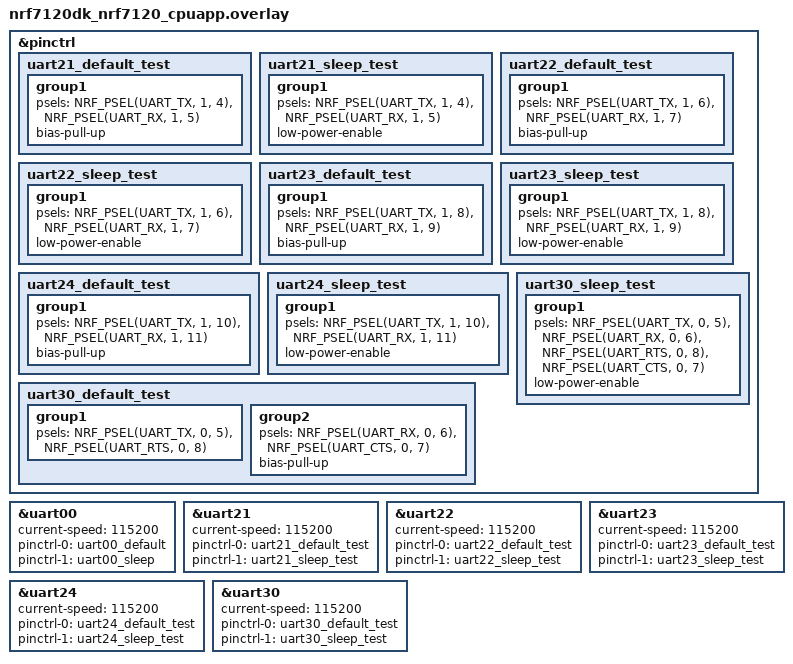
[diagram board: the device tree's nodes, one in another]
/*
 * Copyright (c) 2026 Nordic Semiconductor ASA
 *
 * SPDX-License-Identifier: LicenseRef-Nordic-5-Clause
 */

&pinctrl {
	uart21_default_test: uart21_default_test {
		group1 {
			psels = <NRF_PSEL(UART_TX, 1, 4)>,
				<NRF_PSEL(UART_RX, 1, 5)>;
			bias-pull-up;
		};
	};

	uart21_sleep_test: uart21_sleep_test {
		group1 {
			psels = <NRF_PSEL(UART_TX, 1, 4)>,
				<NRF_PSEL(UART_RX, 1, 5)>;
			low-power-enable;
		};
	};

	uart22_default_test: uart22_default_test {
		group1 {
			psels = <NRF_PSEL(UART_TX, 1, 6)>,
				<NRF_PSEL(UART_RX, 1, 7)>;
			bias-pull-up;
		};
	};

	uart22_sleep_test: uart22_sleep_test {
		group1 {
			psels = <NRF_PSEL(UART_TX, 1, 6)>,
				<NRF_PSEL(UART_RX, 1, 7)>;
			low-power-enable;
		};
	};

	uart23_default_test: uart23_default_test {
		group1 {
			psels = <NRF_PSEL(UART_TX, 1, 8)>,
				<NRF_PSEL(UART_RX, 1, 9)>;
			bias-pull-up;
		};
	};

	uart23_sleep_test: uart23_sleep_test {
		group1 {
			psels = <NRF_PSEL(UART_TX, 1, 8)>,
				<NRF_PSEL(UART_RX, 1, 9)>;
			low-power-enable;
		};
	};

	uart24_default_test: uart24_default_test {
		group1 {
			psels = <NRF_PSEL(UART_TX, 1, 10)>,
				<NRF_PSEL(UART_RX, 1, 11)>;
			bias-pull-up;
		};
	};

	uart24_sleep_test: uart24_sleep_test {
		group1 {
			psels = <NRF_PSEL(UART_TX, 1, 10)>,
				<NRF_PSEL(UART_RX, 1, 11)>;
			low-power-enable;
		};
	};

	uart30_default_test: uart30_default_test {
		group1 {
			psels = <NRF_PSEL(UART_TX, 0, 5)>,
				<NRF_PSEL(UART_RTS, 0, 8)>;
		};

		group2 {
			psels = <NRF_PSEL(UART_RX, 0, 6)>,
				<NRF_PSEL(UART_CTS, 0, 7)>;
			bias-pull-up;
		};
	};

	uart30_sleep_test: uart30_sleep_test {
		group1 {
			psels = <NRF_PSEL(UART_TX, 0, 5)>,
				<NRF_PSEL(UART_RX, 0, 6)>,
				<NRF_PSEL(UART_RTS, 0, 8)>,
				<NRF_PSEL(UART_CTS, 0, 7)>;
			low-power-enable;
		};
	};
};

&uart00 {
	status = "okay";
	current-speed = <115200>;
	pinctrl-0 = <&uart00_default>;
	pinctrl-1 = <&uart00_sleep>;
	pinctrl-names = "default", "sleep";
};

&uart21 {
	status = "okay";
	current-speed = <115200>;
	pinctrl-0 = <&uart21_default_test>;
	pinctrl-1 = <&uart21_sleep_test>;
	pinctrl-names = "default", "sleep";
};

&uart22 {
	status = "okay";
	current-speed = <115200>;
	pinctrl-0 = <&uart22_default_test>;
	pinctrl-1 = <&uart22_sleep_test>;
	pinctrl-names = "default", "sleep";
};

&uart23 {
	status = "okay";
	current-speed = <115200>;
	pinctrl-0 = <&uart23_default_test>;
	pinctrl-1 = <&uart23_sleep_test>;
	pinctrl-names = "default", "sleep";
};

&uart24 {
	status = "okay";
	current-speed = <115200>;
	pinctrl-0 = <&uart24_default_test>;
	pinctrl-1 = <&uart24_sleep_test>;
	pinctrl-names = "default", "sleep";
};

&uart30 {
	status = "okay";
	current-speed = <115200>;
	pinctrl-0 = <&uart30_default_test>;
	pinctrl-1 = <&uart30_sleep_test>;
	pinctrl-names = "default", "sleep";
};
